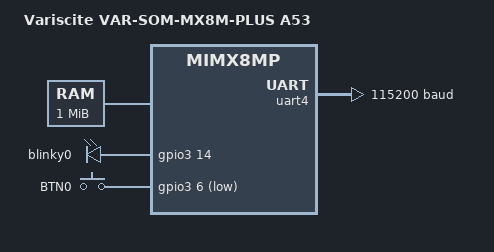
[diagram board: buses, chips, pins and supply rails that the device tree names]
/*
 * Copyright 2025 Variscite Ltd.
 * Copyright 2021-2024 NXP
 *
 * SPDX-License-Identifier: Apache-2.0
 */

/dts-v1/;

#include <nxp/nxp_mimx8mp_a53.dtsi>
#include "imx8mp_var_som-pinctrl.dtsi"
#include <zephyr/dt-bindings/gpio/gpio.h>
#include <zephyr/dt-bindings/input/input-event-codes.h>

/ {
	model = "Variscite VAR-SOM-MX8M-PLUS A53";
	compatible = "fsl,mimx8mp";

	chosen {
		zephyr,console = &uart4;
		zephyr,shell-uart = &uart4;
		/* sram node actually locates at DDR DRAM */
		zephyr,sram = &dram;
	};

	cpus {
		cpu@0 {
			status = "disabled";
		};

		cpu@1 {
			status = "disabled";
		};

		cpu@2 {
			status = "disabled";
		};
	};

	dram: memory@40480000 {
		reg = <0x40480000 DT_SIZE_M(1)>;
	};

	aliases {
		led0 = &blinky0;
		sw0 = &button0;
	};

	leds {
		compatible = "gpio-leds";

		blinky0: blinky_0 {
			gpios = <&gpio3 14 GPIO_ACTIVE_HIGH>;
		};
	};

	keys {
		compatible = "gpio-keys";

		button0: btn_0 {
			label = "BTN0";
			gpios = <&gpio3 6 (GPIO_PULL_UP | GPIO_ACTIVE_LOW)>;
			zephyr,code = <INPUT_KEY_0>;
		};
	};
};

&uart4 {
	status = "okay";
	current-speed = <115200>;
	clocks = <&ccm IMX_CCM_UART4_CLK 0x6c 24>;
	pinctrl-0 = <&uart4_default>;
	pinctrl-names = "default";
};

&gpio3 {
	status = "okay";
};
